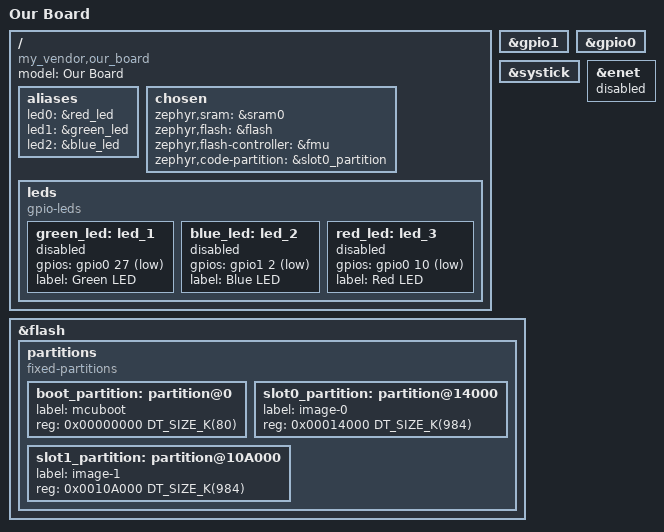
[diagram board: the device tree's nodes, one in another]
/dts-v1/;
#include "our_board.dts"

/ {
    model = "Our Board";
	compatible = "my_vendor,our_board";

    aliases{
        led0 = &red_led;
		led1 = &green_led;
		led2 = &blue_led;
    };

    chosen{
        zephyr,sram = &sram0;
		zephyr,flash = &flash;
		zephyr,flash-controller = &fmu;
		zephyr,code-partition = &slot0_partition;
    };

    leds{
        compatible = "gpio-leds";
		green_led: led_1 {
			gpios = <&gpio0 27 GPIO_ACTIVE_LOW>;
			label = "Green LED";
			status = "disabled";
		};
		blue_led: led_2 {
			gpios = <&gpio1 2 GPIO_ACTIVE_LOW>;
			label = "Blue LED";
			status = "disabled";
		};
		red_led: led_3 {
			gpios = <&gpio0 10 GPIO_ACTIVE_LOW>;
			label = "Red LED";
			status = "disabled";
		};
    };
};

&gpio1 {
	status = "okay";
    };

&gpio0 {
	status = "okay";
};

&systick {
	status = "okay";
};

&enet {
	status = "disabled";
};

&flash {
	partitions {
		compatible = "fixed-partitions";
		#address-cells = <1>;
		#size-cells = <1>;

		/*
		 * Partition sizes must be aligned
		 * to the flash memory sector size of 8KB.
		 */
		boot_partition: partition@0 {
			label = "mcuboot";
			reg = <0x00000000 DT_SIZE_K(80)>;
            };
		slot0_partition: partition@14000 {
			label = "image-0";
			reg = <0x00014000 DT_SIZE_K(984)>;
            };
		slot1_partition: partition@10A000 {
			label = "image-1";
			reg = <0x0010A000 DT_SIZE_K(984)>;
            };
		/* storage_partition is placed in WINBOND flash memory*/
        };
};
